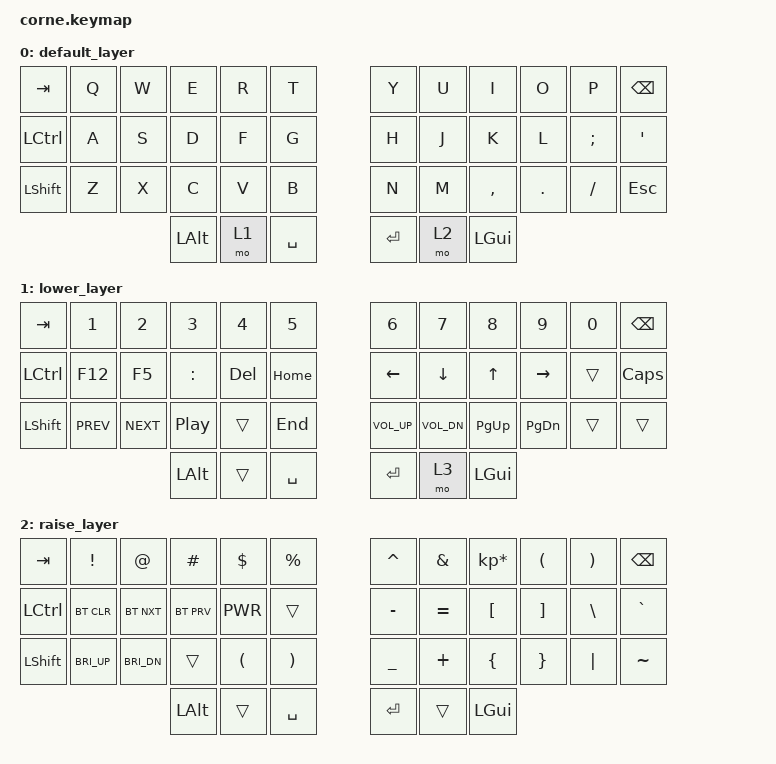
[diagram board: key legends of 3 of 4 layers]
/*
 * Copyright (c) 2020 The ZMK Contributors
 *
 * SPDX-License-Identifier: MIT
 */

#include <behaviors.dtsi>
#include <dt-bindings/zmk/keys.h>
#include <dt-bindings/zmk/bt.h>
#define default_layer 0
#define lower_layer 1
#define raise_layer 2
#define top_layer 3

/ {
        keymap {
                compatible = "zmk,keymap";

                default_layer {
// -----------------------------------------------------------------------------------------
// |  TAB |  Q  |  W  |  E  |  R  |  T  |   |  Y  |  U   |  I  |  O  |  P  | BKSP |
// | CTRL |  A  |  S  |  D  |  F  |  G  |   |  H  |  J   |  K  |  L  |  ;  |  '   |
// | SHFT |  Z  |  X  |  C  |  V  |  B  |   |  N  |  M   |  ,  |  .  |  /  | ESC  |
//                    | ALT | LWR | SPC |   | ENT | RSE  | GUI |
                        bindings = <
   &kp TAB   &kp Q &kp W &kp E &kp R &kp T   &kp Y &kp U  &kp I     &kp O   &kp P    &kp BSPC
   &kp LCTRL &kp A &kp S &kp D &kp F &kp G   &kp H &kp J  &kp K     &kp L   &kp SEMI &kp SQT
   &kp LSHFT &kp Z &kp X &kp C &kp V &kp B   &kp N &kp M  &kp COMMA &kp DOT &kp FSLH &kp ESC
                  &kp LALT &mo 1 &kp SPACE   &kp RET &mo 2 &kp LGUI
                        >;
                };
                lower_layer {
// -----------------------------------------------------------------------------------------
// |  TAB |  1  |  2  |  3  |  4  |  5  |   |  6  |  7  |  8  |  9  |  0  | BKSP |
// | BTCLR| BT1 | BT2 | BT3 | BT4 | BT5 |   | LFT | DWN |  UP | RGT |     |      |
// | SHFT |     |     |     |     |     |   |     |     |     |     |     |      |
//                    | GUI |     | SPC |   | ENT |     | ALT |
                        bindings = <
             &kp TAB &kp N1  &kp N2  &kp N3 &kp N4  &kp N5     &kp N6 &kp N7 &kp N8 &kp N9 &kp N0 &kp BSPC
       &kp LCTRL &kp F12 &kp F5 &kp COLON &kp DEL &kp HOME     &kp LEFT &kp DOWN &kp UP &kp RIGHT &trans &kp CAPSLOCK
   &kp LSHFT &kp C_PREV &kp C_NEXT &kp C_PP &trans &kp END     &kp C_VOL_UP &kp C_VOL_DN &kp PG_UP &kp PG_DN &trans &trans
                                &kp LALT &trans  &kp SPACE     &kp RET  &mo 3   &kp LGUI
                        >;
                };

                raise_layer {
// -----------------------------------------------------------------------------------------
// |  TAB |  !  |  @  |  #  |  $  |  %  |   |  ^  |  &  |  *  |  (  |  )  | BKSP |
// | CTRL |     |     |     |     |     |   |  -  |  =  |  [  |  ]  |  \  |  `   |
// | SHFT |     |     |     |     |     |   |  _  |  +  |  {  |  }  | "|" |  ~   |
//                    | GUI |     | SPC |   | ENT |     | ALT |
                        bindings = <
   &kp TAB   &kp EXCL   &kp AT     &kp HASH   &kp DLLR   &kp PRCNT    &kp CARET &kp AMPS  &kp KP_MULTIPLY  &kp LPAR &kp RPAR &kp BSPC
   &kp LCTRL &bt BT_CLR &bt BT_NXT &bt BT_PRV &kp K_PWR  &trans       &kp MINUS &kp EQUAL &kp LBKT &kp RBKT &kp BSLH &kp GRAVE
   &kp LSHFT &kp C_BRI_UP &kp C_BRI_DN &trans  &kp LPAR  &kp RPAR      &kp UNDER &kp PLUS  &kp LBRC        &kp RBRC &kp PIPE &kp TILDE
                    	     &kp LALT &trans   &kp SPACE   &kp RET    &trans    &kp LGUI
                        >;
                };
                top_layer {
// -----------------------------------------------------------------------------------------
// |  TAB |  Q  |  W  |  E  |  R  |  T  |   |  Y  |  U   |  I  |  O  |  P  | BKSP |
// | CTRL |  A  |  S  |  D  |  F  |  G  |   |  H  |  J   |  K  |  L  |  ;  |  '   |
// | SHFT |  Z  |  X  |  C  |  V  |  B  |   |  N  |  M   |  ,  |  .  |  /  | ESC  |
//                    | ALT | LWR | SPC |   | ENT | RSE  | GUI |
                        bindings = <
   &kp TAB &kp F1 &kp F2 &kp F3 &kp F4 &kp F5                           &kp F6 &kp F7 &kp F8 &kp F9 &kp F10 &kp F11
   &kp LCTRL &kp &trans &kp &trans &kp &trans &kp &trans &kp &trans     &kp &trans &kp &trans  &kp &trans &kp &trans &kp &trans &kp F12
   &kp LSHFT &kp &trans &kp &trans &kp &trans &kp&trans &kp &trans      &kp &trans &kp &trans  &kp &trans &kp &trans &kp &trans &kp &trans
                                          &kp LALT &mo 1 &kp SPACE      &kp RET &mo 2 &kp LGUI
                          >;
                 };
        };
};
